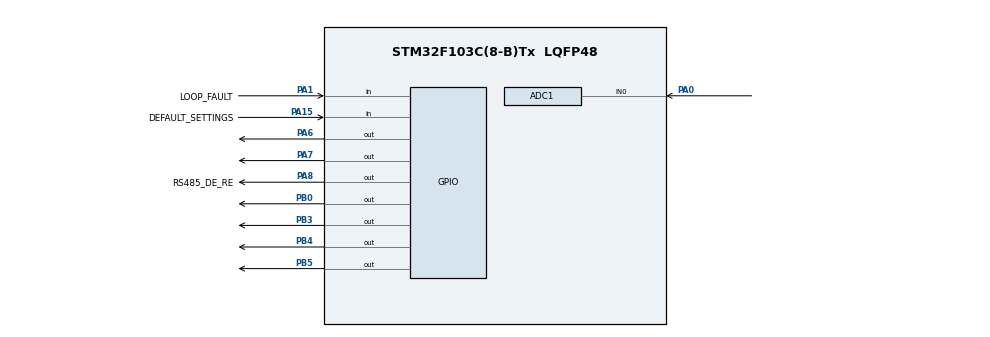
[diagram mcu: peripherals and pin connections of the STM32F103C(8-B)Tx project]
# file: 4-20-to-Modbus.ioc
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ADC1.Channel-1\#ChannelRegularConversion=ADC_CHANNEL_0
ADC1.EnableAnalogWatchDog=false
ADC1.NbrOfConversionFlag=1
ADC1.Rank-1\#ChannelRegularConversion=1
ADC1.SamplingTime-1\#ChannelRegularConversion=ADC_SAMPLETIME_239CYCLES_5
ADC1.master=1
Mcu.Family=STM32F1
Mcu.Name=STM32F103C(8-B)Tx
Mcu.Package=LQFP48
NVIC.PriorityGroup=NVIC_PRIORITYGROUP_4
NVIC.TIM4_IRQn=true\:15\:0\:false\:false\:true\:false\:true\:true
NVIC.TimeBase=TIM4_IRQn
NVIC.TimeBaseIP=TIM4
PA0-WKUP.Signal=ADCx_IN0
PA1.GPIO_Label=LOOP_FAULT
PA1.Signal=GPIO_Input
PA10.Signal=USART1_RX
PA13.Mode=Serial_Wire
PA13.Signal=SYS_JTMS-SWDIO
PA14.Mode=Serial_Wire
PA14.Signal=SYS_JTCK-SWCLK
PA15.GPIO_Label=DEFAULT_SETTINGS
PA15.Signal=GPIO_Input
PA6.Signal=GPIO_Output
PA7.Signal=GPIO_Output
PA8.GPIO_Label=RS485_DE_RE
PA8.PinState=GPIO_PIN_RESET
PA8.Signal=GPIO_Output
PA9.Signal=USART1_TX
PB0.Signal=GPIO_Output
PB3.Signal=GPIO_Output
PB4.Signal=GPIO_Output
PB5.Signal=GPIO_Output
ProjectManager.HeapSize=0x200
ProjectManager.StackSize=0x400
ProjectManager.TargetToolchain=STM32CubeIDE
RCC.ADCPresc=RCC_ADCPCLK2_DIV8
RCC.AHBFreq_Value=64000000
RCC.APB1CLKDivider=RCC_HCLK_DIV2
RCC.APB1Freq_Value=32000000
RCC.APB1TimFreq_Value=64000000
RCC.APB2Freq_Value=64000000
RCC.APB2TimFreq_Value=64000000
RCC.HCLKFreq_Value=64000000
RCC.PLLMUL=RCC_PLL_MUL16
RCC.SYSCLKFreq_VALUE=64000000
RCC.SYSCLKSource=RCC_SYSCLKSOURCE_PLLCLK
RCC.USBFreq_Value=64000000
SH.ADCx_IN0.0=ADC2_IN0
SH.ADCx_IN0.1=ADC1_IN0,IN0
VP_SYS_VS_tim4.Mode=TIM4
board=custom

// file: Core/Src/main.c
/* USER CODE BEGIN Header */
/**
 ******************************************************************************
 * @file           : main.c
 * @brief          : Main program body
 ******************************************************************************
 * @attention
 *
 * Copyright (c) 2026 STMicroelectronics.
 * All rights reserved.
 *
 * This software is licensed under terms that can be found in the LICENSE file
 * in the root directory of this software component.
 * If no LICENSE file comes with this software, it is provided AS-IS.
 *
 ******************************************************************************
 */
/* USER CODE END Header */
#include "main.h"
#include "adc.h"
#include "gpio.h"

/* USER CODE BEGIN Includes */
#include "App.h"
#include "Health.h"
/* USER CODE END Includes */

void SystemClock_Config(void);

/* USER CODE BEGIN 0 */
volatile uint32_t core_state[6];

/* USER CODE END 0 */

int main(void)
{

  /* MCU Configuration--------------------------------------------------------*/

  /* Reset of all peripherals, Initializes the Flash interface and the Systick. */
  HAL_Init();

  /* Configure the system clock */
  SystemClock_Config();

  /* Initialize all configured peripherals */
  MX_GPIO_Init();
  MX_ADC1_Init();
  /* USER CODE BEGIN 2 */

    /*LL_ADC_Enable(ADC1);
    HAL_Delay(1);

    LL_ADC_StartCalibration(ADC1);

    while (LL_ADC_IsCalibrationOnGoing(ADC1))
    {
    }*/

    App_Start();

  /* USER CODE END 2 */

  /* Infinite loop */
    while (1)
    {

    }
}

void SystemClock_Config(void)
{
  LL_FLASH_SetLatency(LL_FLASH_LATENCY_2);
  while(LL_FLASH_GetLatency()!= LL_FLASH_LATENCY_2)
  {
  }
  LL_RCC_HSI_SetCalibTrimming(16);
  LL_RCC_HSI_Enable();

   /* Wait till HSI is ready */
  while(LL_RCC_HSI_IsReady() != 1)
  {

  }
  LL_RCC_PLL_ConfigDomain_SYS(LL_RCC_PLLSOURCE_HSI_DIV_2, LL_RCC_PLL_MUL_16);
  LL_RCC_PLL_Enable();

   /* Wait till PLL is ready */
  while(LL_RCC_PLL_IsReady() != 1)
  {

  }
  LL_RCC_SetAHBPrescaler(LL_RCC_SYSCLK_DIV_1);
  LL_RCC_SetAPB1Prescaler(LL_RCC_APB1_DIV_2);
  LL_RCC_SetAPB2Prescaler(LL_RCC_APB2_DIV_1);
  LL_RCC_SetSysClkSource(LL_RCC_SYS_CLKSOURCE_PLL);

   /* Wait till System clock is ready */
  while(LL_RCC_GetSysClkSource() != LL_RCC_SYS_CLKSOURCE_STATUS_PLL)
  {

  }
  LL_SetSystemCoreClock(64000000);

   /* Update the time base */
  if (HAL_InitTick (TICK_INT_PRIORITY) != HAL_OK)
  {
    Error_Handler();
  }
  LL_RCC_SetADCClockSource(LL_RCC_ADC_CLKSRC_PCLK2_DIV_8);
}

void HAL_TIM_PeriodElapsedCallback(TIM_HandleTypeDef *htim)
{
  if (htim->Instance == TIM4)
  {
    HAL_IncTick();
  }
}

void Error_Handler(void)
{
  /* USER CODE BEGIN Error_Handler_Debug */
    /* User can add his own implementation to report the HAL error return state */
    Health_Panic(FAULT_ERROR_HANDLER);
  /* USER CODE END Error_Handler_Debug */
}
